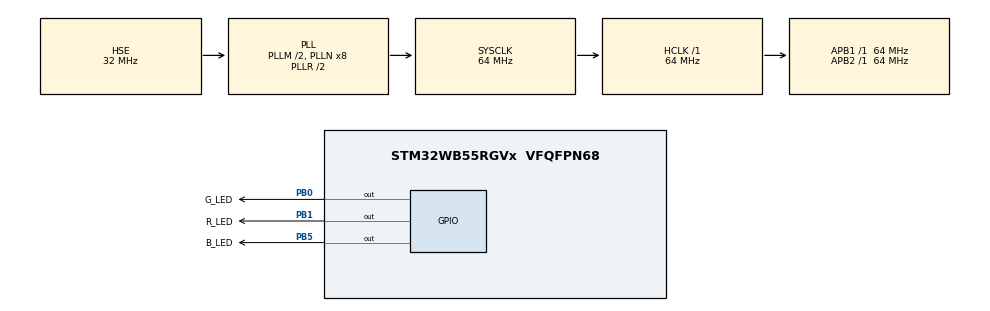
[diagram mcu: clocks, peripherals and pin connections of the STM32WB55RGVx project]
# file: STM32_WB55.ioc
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Mcu.Family=STM32WB
Mcu.Name=STM32WB55RGVx
Mcu.Package=VFQFPN68
NVIC.HSEM_IRQn=true\:0\:0\:false\:false\:true\:false\:true\:true
NVIC.IPCC_C1_RX_IRQn=true\:0\:0\:false\:false\:true\:true\:true\:true
NVIC.IPCC_C1_TX_IRQn=true\:0\:0\:false\:false\:true\:true\:true\:true
NVIC.PriorityGroup=NVIC_PRIORITYGROUP_4
OSC_IN.Mode=HSE-External-Oscillator
OSC_IN.Signal=RCC_OSC_IN
OSC_OUT.Mode=HSE-External-Oscillator
OSC_OUT.Signal=RCC_OSC_OUT
PB0.GPIO_Label=G_LED
PB0.Signal=GPIO_Output
PB1.GPIO_Label=R_LED
PB1.Signal=GPIO_Output
PB5.GPIO_Label=B_LED
PB5.Signal=GPIO_Output
ProjectManager.HeapSize=0x200
ProjectManager.StackSize=0x400
ProjectManager.TargetToolchain=STM32CubeIDE
RCC.ADCFreq_Value=64000000
RCC.AHB2CLKDivider=RCC_SYSCLK_DIV2
RCC.AHBFreq_Value=64000000
RCC.APB1Freq_Value=64000000
RCC.APB1TimFreq_Value=64000000
RCC.APB2Freq_Value=64000000
RCC.APB2TimFreq_Value=64000000
RCC.APB3Freq_Value=16000000
RCC.Cortex2_Div=SYSTICK_CLKSOURCE_HCLK_DIV8
RCC.CortexFreq_Value=64000000
RCC.HCLKFreq_Value=64000000
RCC.HSE_VALUE=32000000
RCC.HSI48_VALUE=48000000
RCC.HSI_VALUE=16000000
RCC.LSE_VALUE=32768
RCC.PLLM=RCC_PLLM_DIV2
RCC.PLLSourceVirtual=RCC_PLLSOURCE_HSE
RCC.SYSCLKFreq_VALUE=64000000
RCC.SYSCLKSource=RCC_SYSCLKSOURCE_PLLCLK
RCC.USBFreq_Value=64000000
RCC.VCOOutputFreq_Value=128000000
RF1.Mode=RF1_Activate
RF1.Signal=RF_RF1
STM32_WPAN.AD_TYPE_COMPLETE_LOCAL_NAME=STM32WB55EE
STM32_WPAN.AD_TYPE_COMPLETE_LOCAL_NAME_LENGTH=12
STM32_WPAN.CFG_GAP_DEVICE_NAME=STM32WB55
STM32_WPAN.CFG_GAP_DEVICE_NAME_LENGTH=9
STM32_WPAN.CUSTOM_TEMPLATE=Enabled
STM32_WPAN.GAP_CENTRAL_ROLE=4
STM32_WPAN.GAP_OBSERVER_ROLE=8
STM32_WPAN.GAP_PERIPHERAL_ROLE=1
STM32_WPAN.INCLUDE_AD_TYPE_COMPLETE_LOCAL_NAME=1
STM32_WPAN.INCLUDE_AD_TYPE_TX_POWER_LEVEL=0
STM32_WPAN.LOCAL_NAME=MY_BLE
STM32_WPAN.LOCAL_NAME_FORMATTED=,'M','Y','_','B','L','E'
STM32_WPAN.NUMBER_OF_SERVICES=1
STM32_WPAN.SERVICE1_CHAR1_LONG_NAME=MY_TX_CHAR
STM32_WPAN.SERVICE1_CHAR1_PROP_NOTIFY=CHAR_PROP_NOTIFY
STM32_WPAN.SERVICE1_CHAR1_SHORT_NAME=MY_TX_CHAR
STM32_WPAN.SERVICE1_CHAR1_UUID=12 34
STM32_WPAN.SERVICE1_CHAR1_VALUE_LENGTH=20
STM32_WPAN.SERVICE1_CHAR2_LONG_NAME=MY_RX_CHAR
STM32_WPAN.SERVICE1_CHAR2_PROP_WRITE_WITHOUT_RESP=CHAR_PROP_WRITE_WITHOUT_RESP
STM32_WPAN.SERVICE1_CHAR2_SHORT_NAME=MY_RX_CHAR
STM32_WPAN.SERVICE1_CHAR2_UUID=12 35
STM32_WPAN.SERVICE1_CHAR2_VALUE_LENGTH=20
STM32_WPAN.SERVICE1_LONG_NAME=My_Services
STM32_WPAN.SERVICE1_NUMBER_OF_CHARACTERISTICS=2
STM32_WPAN.SERVICE1_SHORT_NAME=My_Services
STM32_WPAN.SERVICE1_UUID=56 78
VP_CRC_VS_CRC.Mode=CRC_Activate
VP_HSEM_VS_HSEM.Mode=HSEM_Activate
VP_IPCC_VS_IPCC.Mode=IPCC_Activate
VP_MEMORYMAP_VS_MEMORYMAP.Mode=CurAppReg
VP_RTC_VS_RTC_Activate.Mode=RTC_Enabled
VP_RTC_VS_RTC_Calendar.Mode=RTC_Calendar
VP_SEQUENCER_VS_SEQUENCER.Mode=SEQUENCER_Enabled
VP_STM32_WPAN_VS_BLE_HOST.Mode=STM32_WPAN_Enabled
VP_TINY_LPM_VS_TINY_LPM.Mode=TINY_LPM_Enabled
board=custom

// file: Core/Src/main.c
/* USER CODE BEGIN Header */
/**
  ******************************************************************************
  * @file           : main.c
  * @brief          : Main program body
  ******************************************************************************
  * @attention
  *
  * Copyright (c) 2026 STMicroelectronics.
  * All rights reserved.
  *
  * This software is licensed under terms that can be found in the LICENSE file
  * in the root directory of this software component.
  * If no LICENSE file comes with this software, it is provided AS-IS.
  *
  ******************************************************************************
  */
/* USER CODE END Header */
#include "main.h"
#include "crc.h"
#include "ipcc.h"
#include "rf.h"
#include "rtc.h"
#include "gpio.h"

void SystemClock_Config(void);
void PeriphCommonClock_Config(void);

/* USER CODE BEGIN 0 */
extern uint8_t Send_Data_To_Phone(uint8_t *data, uint16_t length);
extern void Send_Test_Data(void);

uint32_t lastTestSendTime;
/* USER CODE END 0 */

int main(void)
{

  /* MCU Configuration--------------------------------------------------------*/

  /* Reset of all peripherals, Initializes the Flash interface and the Systick. */
  HAL_Init();
  /* Config code for STM32_WPAN (HSE Tuning must be done before system clock configuration) */
  MX_APPE_Config();

  /* Configure the system clock */
  SystemClock_Config();

  /* Configure the peripherals common clocks */
  PeriphCommonClock_Config();

  /* IPCC initialisation */
  MX_IPCC_Init();

  /* Initialize all configured peripherals */
  MX_GPIO_Init();
  MX_CRC_Init();
  MX_RTC_Init();
  MX_RF_Init();

  /* Init code for STM32_WPAN */
  MX_APPE_Init();

  /* Infinite loop */
  while (1)
  {
    MX_APPE_Process();

    /* USER CODE BEGIN 3 */
    if (HAL_GetTick() - lastTestSendTime > 1000) {
                // Check if we're connected (notificationsEnabled is in custom_app.c)
                // We'll check by trying to send, or use a global flag
                Send_Test_Data();
                lastTestSendTime = HAL_GetTick();
        }
  }
  /* USER CODE END 3 */
}

void SystemClock_Config(void)
{
  RCC_OscInitTypeDef RCC_OscInitStruct = {0};
  RCC_ClkInitTypeDef RCC_ClkInitStruct = {0};

  /** Configure the main internal regulator output voltage
  */
  __HAL_PWR_VOLTAGESCALING_CONFIG(PWR_REGULATOR_VOLTAGE_SCALE1);

  /** Initializes the RCC Oscillators according to the specified parameters
  * in the RCC_OscInitTypeDef structure.
  */
  RCC_OscInitStruct.OscillatorType = RCC_OSCILLATORTYPE_HSI|RCC_OSCILLATORTYPE_LSI1
                              |RCC_OSCILLATORTYPE_HSE;
  RCC_OscInitStruct.HSEState = RCC_HSE_ON;
  RCC_OscInitStruct.HSIState = RCC_HSI_ON;
  RCC_OscInitStruct.HSICalibrationValue = RCC_HSICALIBRATION_DEFAULT;
  RCC_OscInitStruct.LSIState = RCC_LSI_ON;
  RCC_OscInitStruct.PLL.PLLState = RCC_PLL_ON;
  RCC_OscInitStruct.PLL.PLLSource = RCC_PLLSOURCE_HSE;
  RCC_OscInitStruct.PLL.PLLM = RCC_PLLM_DIV2;
  RCC_OscInitStruct.PLL.PLLN = 8;
  RCC_OscInitStruct.PLL.PLLP = RCC_PLLP_DIV2;
  RCC_OscInitStruct.PLL.PLLR = RCC_PLLR_DIV2;
  RCC_OscInitStruct.PLL.PLLQ = RCC_PLLQ_DIV2;
  if (HAL_RCC_OscConfig(&RCC_OscInitStruct) != HAL_OK)
  {
    Error_Handler();
  }

  /** Configure the SYSCLKSource, HCLK, PCLK1 and PCLK2 clocks dividers
  */
  RCC_ClkInitStruct.ClockType = RCC_CLOCKTYPE_HCLK4|RCC_CLOCKTYPE_HCLK2
                              |RCC_CLOCKTYPE_HCLK|RCC_CLOCKTYPE_SYSCLK
                              |RCC_CLOCKTYPE_PCLK1|RCC_CLOCKTYPE_PCLK2;
  RCC_ClkInitStruct.SYSCLKSource = RCC_SYSCLKSOURCE_PLLCLK;
  RCC_ClkInitStruct.AHBCLKDivider = RCC_SYSCLK_DIV1;
  RCC_ClkInitStruct.APB1CLKDivider = RCC_HCLK_DIV1;
  RCC_ClkInitStruct.APB2CLKDivider = RCC_HCLK_DIV1;
  RCC_ClkInitStruct.AHBCLK2Divider = RCC_SYSCLK_DIV2;
  RCC_ClkInitStruct.AHBCLK4Divider = RCC_SYSCLK_DIV1;

  if (HAL_RCC_ClockConfig(&RCC_ClkInitStruct, FLASH_LATENCY_3) != HAL_OK)
  {
    Error_Handler();
  }
}

void PeriphCommonClock_Config(void)
{
  RCC_PeriphCLKInitTypeDef PeriphClkInitStruct = {0};

  /** Initializes the peripherals clock
  */
  PeriphClkInitStruct.PeriphClockSelection = RCC_PERIPHCLK_SMPS|RCC_PERIPHCLK_RFWAKEUP;
  PeriphClkInitStruct.RFWakeUpClockSelection = RCC_RFWKPCLKSOURCE_HSE_DIV1024;
  PeriphClkInitStruct.SmpsClockSelection = RCC_SMPSCLKSOURCE_HSI;
  PeriphClkInitStruct.SmpsDivSelection = RCC_SMPSCLKDIV_RANGE1;

  if (HAL_RCCEx_PeriphCLKConfig(&PeriphClkInitStruct) != HAL_OK)
  {
    Error_Handler();
  }
}

void Error_Handler(void)
{
  __disable_irq();
  while (1)
  {
  }
}
